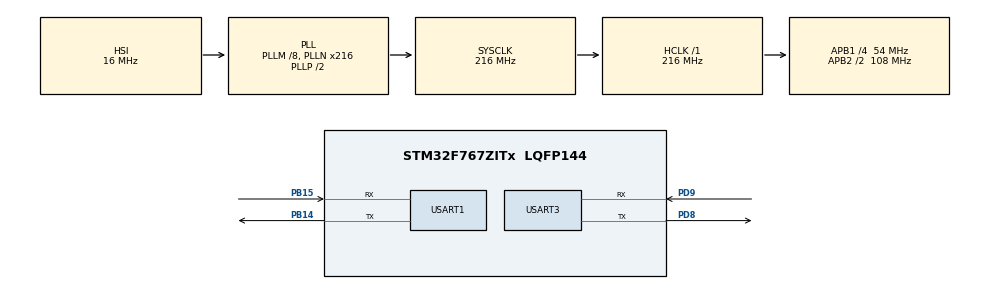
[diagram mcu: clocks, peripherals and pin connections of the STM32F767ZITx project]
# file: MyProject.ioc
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CORTEX_M7.CPU_DCache=Enabled
CORTEX_M7.CPU_ICache=Enabled
Mcu.Family=STM32F7
Mcu.Name=STM32F767ZITx
Mcu.Package=LQFP144
NVIC.PriorityGroup=NVIC_PRIORITYGROUP_4
NVIC.USART1_IRQn=true\:0\:0\:false\:false\:true\:true\:true
PB14.Mode=Asynchronous
PB14.Signal=USART1_TX
PB15.Mode=Asynchronous
PB15.Signal=USART1_RX
PD8.Mode=Asynchronous
PD8.Signal=USART3_TX
PD9.Mode=Asynchronous
PD9.Signal=USART3_RX
ProjectManager.HeapSize=0x2000
ProjectManager.StackSize=0x2000
ProjectManager.TargetToolchain=MDK-ARM V5.27
RCC.AHBFreq_Value=216000000
RCC.APB1CLKDivider=RCC_HCLK_DIV4
RCC.APB1Freq_Value=54000000
RCC.APB1TimFreq_Value=108000000
RCC.APB2CLKDivider=RCC_HCLK_DIV2
RCC.APB2Freq_Value=108000000
RCC.APB2TimFreq_Value=216000000
RCC.CortexFreq_Value=216000000
RCC.HCLKFreq_Value=216000000
RCC.HSE_VALUE=25000000
RCC.HSI_VALUE=16000000
RCC.LSE_VALUE=32768
RCC.PLLM=8
RCC.PLLN=216
RCC.SYSCLKFreq_VALUE=216000000
RCC.SYSCLKSource=RCC_SYSCLKSOURCE_PLLCLK
RCC.USBFreq_Value=216000000
RCC.VCOOutputFreq_Value=432000000
STMicroelectronics.X-CUBE-AI.5.1.2.ActivationBufferSizeList=25680
STMicroelectronics.X-CUBE-AI.5.1.2.ApplicationCcArtificialOoIntelligenceJjApplication=ApplicationTemplate
STMicroelectronics.X-CUBE-AI.5.1.2.HeapSize=0x2000
STMicroelectronics.X-CUBE-AI.5.1.2.InternalRamActivationBufferMaxSize=AI_HARGITHUB_DATA_ACTIVATIONS_SIZE
STMicroelectronics.X-CUBE-AI.5.1.2.LatestDirectoryUsed-5f471efd112f2a83c5bbe0e53d66cb79b922293896adce39e2d645e76ab573b7=D\:\\embadded+ai
STMicroelectronics.X-CUBE-AI.5.1.2.MaximumNumberOfInputLayer=1
STMicroelectronics.X-CUBE-AI.5.1.2.MaximumNumberOfOutputLayer=1
STMicroelectronics.X-CUBE-AI.5.1.2.MaximumSizeOfInputLayer=AI_HARGITHUB_IN_1_SIZE_BYTES
STMicroelectronics.X-CUBE-AI.5.1.2.MaximumSizeOfOutputLayer=AI_HARGITHUB_OUT_1_SIZE_BYTES
STMicroelectronics.X-CUBE-AI.5.1.2.ModelActualCompression-5f471efd112f2a83c5bbe0e53d66cb79b922293896adce39e2d645e76ab573b7=0.0
STMicroelectronics.X-CUBE-AI.5.1.2.ModelCompression-5f471efd112f2a83c5bbe0e53d66cb79b922293896adce39e2d645e76ab573b7=4
STMicroelectronics.X-CUBE-AI.5.1.2.ModelFlashOccupation-5f471efd112f2a83c5bbe0e53d66cb79b922293896adce39e2d645e76ab573b7=794136
STMicroelectronics.X-CUBE-AI.5.1.2.ModelHashList=5f471efd112f2a83c5bbe0e53d66cb79b922293896adce39e2d645e76ab573b7
STMicroelectronics.X-CUBE-AI.5.1.2.ModelKind-5f471efd112f2a83c5bbe0e53d66cb79b922293896adce39e2d645e76ab573b7=KERAS
STMicroelectronics.X-CUBE-AI.5.1.2.ModelMacc-5f471efd112f2a83c5bbe0e53d66cb79b922293896adce39e2d645e76ab573b7=874970
STMicroelectronics.X-CUBE-AI.5.1.2.ModelName-5f471efd112f2a83c5bbe0e53d66cb79b922293896adce39e2d645e76ab573b7=hargithub
STMicroelectronics.X-CUBE-AI.5.1.2.ModelNameList=hargithub
STMicroelectronics.X-CUBE-AI.5.1.2.ModelRamOccupation-5f471efd112f2a83c5bbe0e53d66cb79b922293896adce39e2d645e76ab573b7=25680
STMicroelectronics.X-CUBE-AI.5.1.2.ModelStructureFile-5f471efd112f2a83c5bbe0e53d66cb79b922293896adce39e2d645e76ab573b7=D\:\\embadded+ai\\har_github.h5
STMicroelectronics.X-CUBE-AI.5.1.2.ModelType-5f471efd112f2a83c5bbe0e53d66cb79b922293896adce39e2d645e76ab573b7=Saved model
STMicroelectronics.X-CUBE-AI.5.1.2.StackSize=0x2000
STMicroelectronics.X-CUBE-AI.5.1.2.WorkingBufferStartAddrList=0xFFFFFFFF
STMicroelectronics.X-CUBE-AI.5.1.2.XAaCUBEAaAICcArtificialOoIntelligenceJjCore=true
USART1.VirtualMode-Asynchronous=VM_ASYNC
USART3.VirtualMode-Asynchronous=VM_ASYNC
VP_CRC_VS_CRC.Mode=CRC_Activate
VP_STMicroelectronics.X-CUBE-AI_VS_ArtificialOoIntelligenceJjApplication_5.1.2.Mode=ArtificialOoIntelligenceJjApplication
VP_STMicroelectronics.X-CUBE-AI_VS_ArtificialOoIntelligenceJjXAaCUBEAaAI_5.1.2.Mode=ArtificialOoIntelligenceJjXAaCUBEAaAI
board=custom

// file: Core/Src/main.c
/* USER CODE BEGIN Header */
/**
  ******************************************************************************
  * @file           : main.c
  * @brief          : Main program body
  ******************************************************************************
  * @attention
  *
  * <h2><center>&copy; Copyright (c) 2020 STMicroelectronics.
  * All rights reserved.</center></h2>
  *
  * This software component is licensed by ST under Ultimate Liberty license
  * SLA0044, the "License"; You may not use this file except in compliance with
  * the License. You may obtain a copy of the License at:
  *                             www.st.com/SLA0044
  *
  ******************************************************************************
  */
/* USER CODE END Header */
#include "main.h"
#include "app_x-cube-ai.h"

/* USER CODE BEGIN Includes */
#include "stdio.h"
/* USER CODE END Includes */

CRC_HandleTypeDef hcrc;

UART_HandleTypeDef huart3;
UART_HandleTypeDef huart1;

void SystemClock_Config(void);
static void MX_GPIO_Init(void);
static void MX_CRC_Init(void);
void MX_USART3_UART_Init(void);
void MX_USART1_UART_Init(void);
#define testsize 270*6
 uint8_t tempbuf[testsize];

int main(void)
{

  /* Enable I-Cache---------------------------------------------------------*/
  SCB_EnableICache();

  /* Enable D-Cache---------------------------------------------------------*/
  SCB_EnableDCache();

  /* MCU Configuration--------------------------------------------------------*/

  /* Reset of all peripherals, Initializes the Flash interface and the Systick. */
  HAL_Init();

  /* Configure the system clock */
  SystemClock_Config();

  /* Initialize all configured peripherals */
  MX_GPIO_Init();
  MX_CRC_Init();
  MX_X_CUBE_AI_Init();
  /* USER CODE BEGIN 2 */
	/*
	modify by xfs on 9/24 23:26
	*/
	MX_USART3_UART_Init();  //init USART3
	MX_USART1_UART_Init(); //init USART1
  /* USER CODE END 2 */

  /* Infinite loop */
  /* USER CODE BEGIN WHILE */
	printf("init over\r\n");
  while (1)
  {
    /* USER CODE END WHILE */

  //MX_X_CUBE_AI_Process();
  }
}

void SystemClock_Config(void)
{
  RCC_OscInitTypeDef RCC_OscInitStruct = {0};
  RCC_ClkInitTypeDef RCC_ClkInitStruct = {0};
  RCC_PeriphCLKInitTypeDef PeriphClkInitStruct = {0};

  /** Configure the main internal regulator output voltage
  */
  __HAL_RCC_PWR_CLK_ENABLE();
  __HAL_PWR_VOLTAGESCALING_CONFIG(PWR_REGULATOR_VOLTAGE_SCALE1);
  /** Initializes the RCC Oscillators according to the specified parameters
  * in the RCC_OscInitTypeDef structure.
  */
  RCC_OscInitStruct.OscillatorType = RCC_OSCILLATORTYPE_HSI;
  RCC_OscInitStruct.HSIState = RCC_HSI_ON;
  RCC_OscInitStruct.HSICalibrationValue = RCC_HSICALIBRATION_DEFAULT;
  RCC_OscInitStruct.PLL.PLLState = RCC_PLL_ON;
  RCC_OscInitStruct.PLL.PLLSource = RCC_PLLSOURCE_HSI;
  RCC_OscInitStruct.PLL.PLLM = 8;
  RCC_OscInitStruct.PLL.PLLN = 216;
  RCC_OscInitStruct.PLL.PLLP = RCC_PLLP_DIV2;
  RCC_OscInitStruct.PLL.PLLQ = 2;
  if (HAL_RCC_OscConfig(&RCC_OscInitStruct) != HAL_OK)
  {
    Error_Handler();
  }
  /** Activate the Over-Drive mode
  */
  if (HAL_PWREx_EnableOverDrive() != HAL_OK)
  {
    Error_Handler();
  }
  /** Initializes the CPU, AHB and APB buses clocks
  */
  RCC_ClkInitStruct.ClockType = RCC_CLOCKTYPE_HCLK|RCC_CLOCKTYPE_SYSCLK
                              |RCC_CLOCKTYPE_PCLK1|RCC_CLOCKTYPE_PCLK2;
  RCC_ClkInitStruct.SYSCLKSource = RCC_SYSCLKSOURCE_PLLCLK;
  RCC_ClkInitStruct.AHBCLKDivider = RCC_SYSCLK_DIV1;
  RCC_ClkInitStruct.APB1CLKDivider = RCC_HCLK_DIV4;
  RCC_ClkInitStruct.APB2CLKDivider = RCC_HCLK_DIV2;

  if (HAL_RCC_ClockConfig(&RCC_ClkInitStruct, FLASH_LATENCY_7) != HAL_OK)
  {
    Error_Handler();
  }
  PeriphClkInitStruct.PeriphClockSelection = RCC_PERIPHCLK_USART3;
  PeriphClkInitStruct.Usart3ClockSelection = RCC_USART3CLKSOURCE_PCLK1;
  if (HAL_RCCEx_PeriphCLKConfig(&PeriphClkInitStruct) != HAL_OK)
  {
    Error_Handler();
  }
}

static void MX_CRC_Init(void)
{

  hcrc.Instance = CRC;
  hcrc.Init.DefaultPolynomialUse = DEFAULT_POLYNOMIAL_ENABLE;
  hcrc.Init.DefaultInitValueUse = DEFAULT_INIT_VALUE_ENABLE;
  hcrc.Init.InputDataInversionMode = CRC_INPUTDATA_INVERSION_NONE;
  hcrc.Init.OutputDataInversionMode = CRC_OUTPUTDATA_INVERSION_DISABLE;
  hcrc.InputDataFormat = CRC_INPUTDATA_FORMAT_BYTES;
  if (HAL_CRC_Init(&hcrc) != HAL_OK)
  {
    Error_Handler();
  }

}

void MX_USART3_UART_Init(void)
{

  huart3.Instance = USART3;
  huart3.Init.BaudRate = 115200;
  huart3.Init.WordLength = UART_WORDLENGTH_8B;
  huart3.Init.StopBits = UART_STOPBITS_1;
  huart3.Init.Parity = UART_PARITY_NONE;
  huart3.Init.Mode = UART_MODE_TX_RX;
  huart3.Init.HwFlowCtl = UART_HWCONTROL_NONE;
  huart3.Init.OverSampling = UART_OVERSAMPLING_16;
  huart3.Init.OneBitSampling = UART_ONE_BIT_SAMPLE_DISABLE;
  huart3.AdvancedInit.AdvFeatureInit = UART_ADVFEATURE_NO_INIT;
  if (HAL_UART_Init(&huart3) != HAL_OK)
  {
    Error_Handler();
  }

}

void MX_USART1_UART_Init(void)
{

  huart1.Instance = USART1;
  huart1.Init.BaudRate = 115200;
  huart1.Init.WordLength = UART_WORDLENGTH_8B;
  huart1.Init.StopBits = UART_STOPBITS_1;
  huart1.Init.Parity = UART_PARITY_NONE;
  huart1.Init.Mode = UART_MODE_TX_RX;
  huart1.Init.HwFlowCtl = UART_HWCONTROL_NONE;
  huart1.Init.OverSampling = UART_OVERSAMPLING_16;
  huart1.Init.OneBitSampling = UART_ONE_BIT_SAMPLE_DISABLE;
  huart1.AdvancedInit.AdvFeatureInit = UART_ADVFEATURE_NO_INIT;
  if (HAL_UART_Init(&huart1) != HAL_OK)
  {
    Error_Handler();
  }

	HAL_UART_Receive_IT(&huart1,tempbuf,testsize);

}

void USART1_IRQHandler(void){
	HAL_UART_IRQHandler(&huart1);

}

void HAL_UART_RxCpltCallback(UART_HandleTypeDef *UartHandle)
{

	if(UartHandle==&huart1){
//		for(i = 0 ; i< testsize; i++){
//				printf("%c",tempbuf[i]);
//		}
		MX_X_CUBE_AI_Process();
				//HAL_UART_Transmit(&huart1,tempbuf,testsize,0xffff);
	}
	HAL_UART_Receive_IT(&huart1,tempbuf,testsize);
}
static void MX_GPIO_Init(void)
{

  /* GPIO Ports Clock Enable */
  __HAL_RCC_GPIOD_CLK_ENABLE();

}

/* USER CODE BEGIN 4 */
/*int fputc(int c, FILE * f){
	uint8_t ch;
	ch = c ;
	HAL_UART_Transmit(&huart3,&ch,1,1000);
	return c ;
}*/
int fputc(int ch ,FILE *f){
		HAL_UART_Transmit(&huart1,(uint8_t*)&ch,1,0xffff);
		return ch;
}
/* USER CODE END 4 */

void Error_Handler(void)
{
}

/************************ (C) COPYRIGHT STMicroelectronics *****END OF FILE****/
